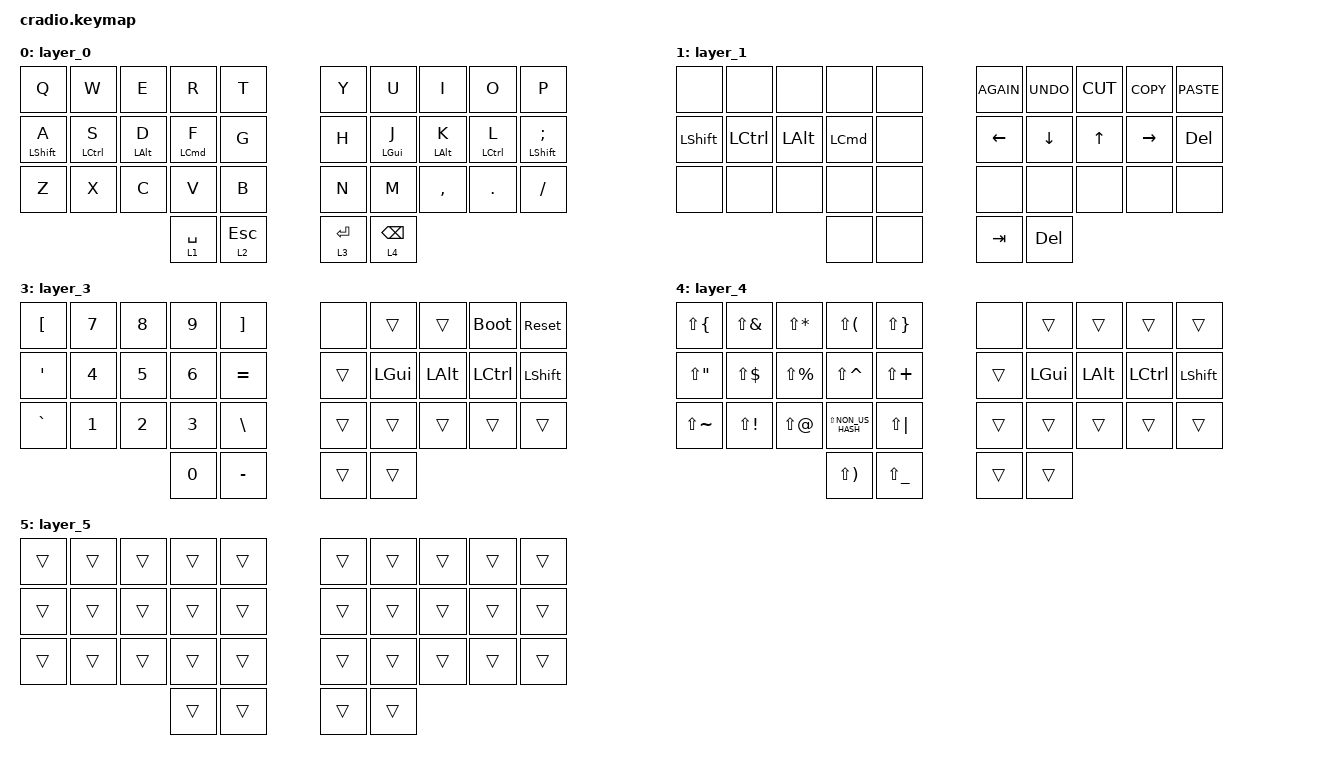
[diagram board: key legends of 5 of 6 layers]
/*
* Copyright (c) 2020 The ZMK Contributors
*
* SPDX-License-Identifier: MIT
*/

#include <behaviors.dtsi>
#include <dt-bindings/zmk/keys.h>

&mt {
    flavor = "tap-preferred";
    quick-tap-ms = <200>;
    require-prior-idle-ms = <125>;
};

/ {
    keymap {
        compatible = "zmk,keymap";

        layer_0 {
            bindings = <
&kp Q             &kp W               &kp E           &kp R               &kp T           &kp Y         &kp U            &kp I           &kp O               &kp P
&mt LEFT_SHIFT A  &mt LEFT_CONTROL S  &mt LEFT_ALT D  &mt LEFT_COMMAND F  &kp G           &kp H         &mt LEFT_GUI J   &mt LEFT_ALT K  &mt LEFT_CONTROL L  &mt LEFT_SHIFT SEMICOLON
&kp Z             &kp X               &kp C           &kp V               &kp B           &kp N         &kp M            &kp COMMA       &kp PERIOD          &kp SLASH
                                                      &lt 1 SPACE         &lt 2 ESCAPE    &lt 3 RETURN  &lt 4 BACKSPACE
            >;
        };

        layer_1 {
            bindings = <
&none           &none             &none         &none             &none    &kp K_AGAIN  &kp K_UNDO      &kp K_CUT     &kp K_COPY  &kp K_PASTE
&kp LEFT_SHIFT  &kp LEFT_CONTROL  &kp LEFT_ALT  &kp LEFT_COMMAND  &none    &kp LEFT     &kp DOWN_ARROW  &kp UP_ARROW  &kp RIGHT   &kp DELETE
&none           &none             &none         &none             &none    &none        &none           &none         &none       &none
                                                &none             &none    &kp TAB      &kp DELETE
            >;
        };

        layer_2 {
            bindings = <
&sys_reset  &bootloader  &none  &none  &none    &none  &none  &none  &none  &none
&none       &none        &none  &none  &none    &none  &none  &none  &none  &none
&none       &none        &none  &none  &none    &none  &none  &none  &none  &none
                                &none
            >;
        };

        layer_3 {
            bindings = <
&kp LBKT   &kp N7  &kp N8  &kp N9  &kp RBKT     &none   &trans    &trans    &bootloader  &sys_reset
&kp SQT    &kp N4  &kp N5  &kp N6  &kp EQUAL    &trans  &kp LGUI  &kp LALT  &kp LCTRL    &kp LSHFT
&kp GRAVE  &kp N1  &kp N2  &kp N3  &kp BSLH     &trans  &trans    &trans    &trans       &trans
                           &kp N0  &kp MINUS    &trans  &trans
            >;
        };

        layer_4 {
            bindings = <
&kp LS(LBRC)   &kp LS(AMPS)  &kp LS(STAR)   &kp LS(LPAR)         &kp LS(RBRC)     &none   &trans    &trans    &trans     &trans
&kp LS(DQT)    &kp LS(DLLR)  &kp LS(PRCNT)  &kp LS(CARET)        &kp LS(PLUS)     &trans  &kp LGUI  &kp LALT  &kp LCTRL  &kp LSHFT
&kp LS(TILDE)  &kp LS(EXCL)  &kp LS(AT)     &kp LS(NON_US_HASH)  &kp LS(PIPE)     &trans  &trans    &trans    &trans     &trans
                                            &kp LS(RPAR)         &kp LS(UNDER)    &trans  &trans
            >;
        };

        layer_5 {
            bindings = <
&trans  &trans  &trans  &trans  &trans    &trans  &trans  &trans  &trans  &trans
&trans  &trans  &trans  &trans  &trans    &trans  &trans  &trans  &trans  &trans
&trans  &trans  &trans  &trans  &trans    &trans  &trans  &trans  &trans  &trans
                        &trans  &trans    &trans  &trans
            >;
        };
    };
};
